# ATtiny441 device description
Architecture: AVR8; Family: tinyAVR
Registers are 8-bit, access not given, no defined reset value unless marked. A register's access mark holds for its fields unless they carry their own. Offsets are from the block's base; [hi:lo] are bit positions; 'fields as' and 'values as' point back to an identical list.

## FUSE — Fuses
Instances: FUSE 0 in fuses
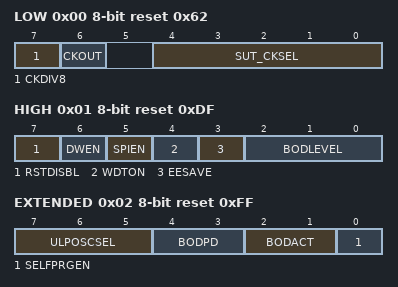
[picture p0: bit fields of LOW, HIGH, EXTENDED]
0x00 LOW reset 0x62
  [7] CKDIV8 — Divide clock by 8 internally
  [6] CKOUT — Clock output on PORTC2
  [4:0] SUT_CKSEL — Select Clock Source
    0=EXTCLK_6CK_16CK_16MS (Ext. Clock; Start-up time PWRDWN/RESET: 6 CK/16 CK + 16 ms); 2=INTRCOSC_8MHZ_6CK_16CK_16MS (Int. RC Osc. 8 MHz; Start-up time PWRDWN/RESET: 6 CK/16 CK + 16 ms); 4=INTULPOSC_32KHZ_6CK_16CK_16MS (Int. ULP Osc.; Start-up time PWRDWN/RESET: 6 CK/16 CK + 16 ms); 6=EXTLOFXTAL_1KCK_16CK_16MS (Ext. Low-Freq. Crystal; Start-up time PWRDWN/RESET: 1K CK/16 CK + 16 ms); 22=EXTLOFXTAL_32KCK_14CK_16MS (Ext. Low-Freq. Crystal; Start-up time PWRDWN/RESET: 32K CK/16 CK + 16 ms); 8=EXTCRES_0MHZ4_0MHZ9_258CK_16CK_16MS (Ext. Ceramic Res. 0.4-0.9 MHz; Start-up time PWRDWN/RESET: 258 CK/16 CK + 16 ms); 24=EXTCRES_0MHZ4_0MHZ9_1KCK_16CK_16MS (Ext. Ceramic Res. 0.4-0.9 MHz; Start-up time PWRDWN/RESET: 1K CK/16 CK + 16 ms); 9=EXTXOSC_0MHZ4_0MHZ9_16KCK_16CK_16MS (Ext. Crystal Osc. 0.4-0.9 MHz; Start-up time PWRDWN/RESET: 16 K CK/16 CK + 16 ms); 10=EXTCRES_0MHZ9_3MHZ_258CK_16CK_16MS (Ext. Ceramic Res. 0.9-3.0 MHz; Start-up time PWRDWN/RESET: 258 CK/16 CK + 16 ms); 26=EXTCRES_0MHZ9_3MHZ_1KCK_16CK_16MS (Ext. Ceramic Res. 0.9-3.0 MHz; Start-up time PWRDWN/RESET: 1K CK/16 CK + 16 ms); 11=EXTXOSC_0MHZ9_3MHZ_16KCK_16CK_16MS (Ext. Crystal Osc. 0.9-3.0 MHz; Start-up time PWRDWN/RESET: 16 K CK/16 CK + 16 ms); 12=EXTCRES_3MHZ_8MHZ_258CK_16CK_16MS (Ext. Ceramic Res. 3.0-8.0 MHz; Start-up time PWRDWN/RESET: 258 CK/16 CK + 16 ms); 28=EXTCRES_3MHZ_8MHZ_1KCK_16CK_16MS (Ext. Ceramic Res. 3.0-8.0 MHz; Start-up time PWRDWN/RESET: 1K CK/16 CK + 16 ms); 13=EXTXOSC_3MHZ_8MHZ_16KCK_16CK_16MS (Ext. Crystal Osc. 3.0-8.0 MHz; Start-up time PWRDWN/RESET: 16 K CK/16 CK + 16 ms); 14=EXTCRES_8MHZ_XX_258CK_16CK_16MS (Ext. Ceramic Res. 8.0- MHz; Start-up time PWRDWN/RESET: 258 CK/16 CK + 16 ms); 30=EXTCRES_8MHZ_XX_1KCK_16CK_16MS (Ext. Ceramic Res. 8.0- MHz; Start-up time PWRDWN/RESET: 1K CK/16 CK + 16 ms); 15=EXTXOSC_8MHZ_XX_16KCK_16CK_16MS (Ext. Crystal Osc. 8.0- MHz; Start-up time PWRDWN/RESET: 16 K CK/16 CK + 16 ms)
0x01 HIGH reset 0xDF
  [7] RSTDISBL — Reset Disabled (Enable PC2 as i/o pin)
  [6] DWEN — Debug Wire enable
  [5] SPIEN — Serial program downloading (SPI) enabled
  [4] WDTON — Watch-dog Timer always on
  [3] EESAVE — Preserve EEPROM through the Chip Erase cycle
  [2:0] BODLEVEL — Brown-out Detector trigger level
    4=4V3 (Brown-out detection at VCC=4.3 V); 5=2V7 (Brown-out detection at VCC=2.7 V); 6=1V8 (Brown-out detection at VCC=1.8 V)
0x02 EXTENDED reset 0xFF
  [7:5] ULPOSCSEL — Frequency selection for internal ULP oscillator. The selection only affects system clock, watchdog and reset timeout always use 32 kHz clock.
    7=ULPOSC_32KHZ (32 kHz); 6=ULPOSC_64KHZ (64 kHz); 5=ULPOSC_128KHZ (128 kHz); 4=ULPOSC_256KHZ (256 kHz); 3=ULPOSC_512KHZ (512 kHz)
  [4:3] BODPD — BOD mode of operation when the device is in sleep mode
    1=BOD_SAMPLED (Sampled); 2=BOD_ENABLED (Enabled); 3=BOD_DISABLED (Disabled)
  [2:1] BODACT — BOD mode of operation when the device is active or idle
    values as BODPD
  [0] SELFPRGEN — Self Programming enable

## LOCKBIT — Lockbits
Instances: LOCKBIT 0 in lockbits
0x00 LOCKBIT reset 0xFF
  [1:0] LB — Memory Lock
    0=PROG_VER_DISABLED (Further programming and verification disabled); 2=PROG_DISABLED (Further programming disabled); 3=NO_LOCK (No memory lock features enabled)

## PORTB — I/O Port
Instances: PORTB 0x00
0x36 PINB bits used 3:0 — Port B Data register
0x37 DDRB bits used 3:0 — Data Direction Register, Port B
0x38 PORTB bits used 3:0 — Input Pins, Port B
0x62 PUEB bits used 3:0 — Pull-up Enable Control Register
0x64 PORTCR — Port Control Register
  [1] BBMB — Break-Before-Make Mode Enable
